# FM33A0XXX register map
File version: 1.0
CPU: SC000 r1p0, little endian, MPU, no FPU, 3 interrupt priority bits
Registers are 32-bit, read-write, reset 0x0 unless marked. A register's access mark holds for its fields unless they carry their own. Offsets are from the block's base; [hi:lo] are bit positions; {n}, {i} and the like mark numbered series.

## SPI1 — SPI Serial Peripheral Interface
Base 0x40000840
Same registers: SPI2 0x40000880
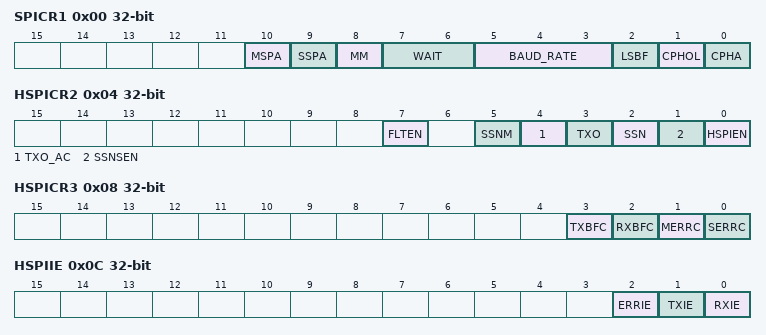
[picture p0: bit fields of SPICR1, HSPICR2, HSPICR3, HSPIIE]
0x00 SPICR1 — SPI Control Register
  [10] MSPA — Master Sampling Position Adjustment, Master MISO
    0=NO_DELAY (NO_DELAY at master MISO); 1=0.5SCK (0.5SCK delay at master MISO)
  [9] SSPA — Slave Sending Position Adjustment, Slave MISO
    0=NO_ADJUST (NO_AHEAD at slave MISO); 1=0.5SCK (0.5SCK ahead at slave MISO)
  [8] MM — Master/Slave mode select
    0=SLAVE (slave mode); 1=Master mode
  [7:6] WAIT — WAIT clock setting at master mode,(1+wait) clock
  [5:3] BAUD_RATE — BAUD_RATE setting
    0=fPCLK (only Master mode); 1=fPCLK/2 (only Master mode); 2=fPCLK/4 (only Master mode); 3=fPCLK/8 (only Master mode); 4=fPCLK/16 (only Master mode); 5=fPCLK/32 (only Master mode); 6=fPCLK/64 (only Master mode); 7=fPCLK/128 (only Master mode)
  [2] LSBF — Frame format bit
    0=MSB (MSB first); 1=LSB (LSB first)
  [1] CPHOL — Clock polarity bit
    0=LOW (Idle clock voltage is low); 1=HIGH (Idle clock voltage is low)
  [0] CPHA — Clock phase bit
    0=FIRST (capture at First edge); 1=SECOND (capture at Second edge)
0x04 HSPICR2 — control Register2
  [7] FLTEN — filter enable for SSN/SCK/MOSI pad
    0=NO_FILTER (no filter for pad input); 1=4NS (filter 4ns for SSN/SCK/MOSI pad)
  [5] SSNM — SSN keep low/high after sending 8bit data at master mode
    0=LOW (SSN keep low after sending 8bit data at master mode); 1=HIGH (SSN keep hign after sending 8bit data at master mode)
  [4] TXO_AC — auto clear at tx_only mode enable
    0=DISABLE (disable auto clear at tx_only mode enable); 1=ENABLE (enable auto clear at tx_only mode enable)
  [3] TXO — TX only
    0=DISABLE (disable tx_only mode); 1=ENABLE (enable tx_only mode)
  [2] SSN — SSN control bit
    0=LOW (SSN output is low voltage); 1=HIGH (SSN output is high voltage)
  [1] SSNSEN — SSN controled by software at master mode
    0=AUTO_OUTPUT (SSN auto output at master mode); 1=SOFTWARE (SSN output controled by software at master mode)
  [0] HSPIEN — HSPI enable bit
    0=DISABLE (HSPI disable); 1=ENABLE (HSPI enable)
0x08 HSPICR3 — control Register3
  [3] TXBFC — Transmit Buffer Clear bit,write 1 to clear
  [2] RXBFC — Receive Buffer Clear bit,write 1 to clear
  [1] MERRC — Master Error Clear bit,write 1 to clear
  [0] SERRC — Slave Error Clear bit,write 1 to clear
0x0C HSPIIE — HSPI interrupt enable Register
  [2] ERRIE — error interrupt enable bit
  [1] TXIE — transmit interrupt enable bit
  [0] RXIE — receive interrupt enable bit
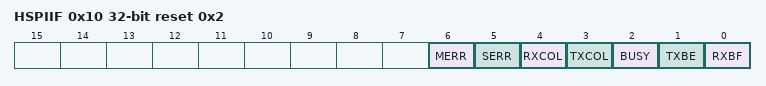
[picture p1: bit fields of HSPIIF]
0x10 HSPIIF reset 0x2 — HSPI interrupt flag Register
  [6] MERR ro — Master Error
  [5] SERR ro — Slave Error
  [4] RXCOL — RX Buffer overflow,write 1 to clear
  [3] TXCOL — TX Buffer overflow,write 1 to clear
  [2] BUSY ro — HSPI transmit flag
  [1] TXBE ro — TX Buffer Empty,write TXBUF clear this bit
  [0] RXBF ro — RX Buffer Full,read RXBUF clear this bit
0x14 HSPITXBUF — HSPI TX buffer Register
  [7:0] TXBUF — TXBUF 8BIT
0x18 HSPIRXBUF — HSPI RX buffer Register
  [7:0] RXBUF — RXBUF 8bit

## GPIOA — GPIO PORTA
Base 0x40000C00
Same registers: GPIOB 0x40000C20, GPIOC 0x40000C40, GPIOD 0x40000C60, GPIOE 0x40000C80, GPIOF 0x40000CA0, GPIOG 0x40000CC0
0x00 INEN — input enable Register
  [15:0] PxINEN — input enable, pin 0-15
0x04 PUEN — pullup enable Register
  [15:0] PxPUEN — IO pull-up control
0x08 ODEN — open-drain Control Register
  [15:0] PxODEN — open-drain control,pin0-15
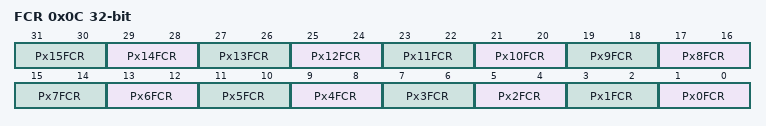
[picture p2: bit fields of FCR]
0x0C FCR — function control Register
  [all] fields
    0=INPUT (GPIO INPUT); 1=OUTPUT (GPIO OUTPUT); 2=Digital function; 3=Analog function
  [2n+1:2n] Px{n}FCR (n=0..15) — Px{n} function select
0x10 ODR reset 0x2 — GPIO output data register
  [15:0] PxDO — PxDO output data
0x14 SETH wo — GPIO output data set register
  [15:0] PxSET — bit set high
0x18 RESETL wo — GPIO output data reset register
  [15:0] PxRESET
0x18 IDR ro — Portx input data register
  [15:0] PxDIN — Portx input data
